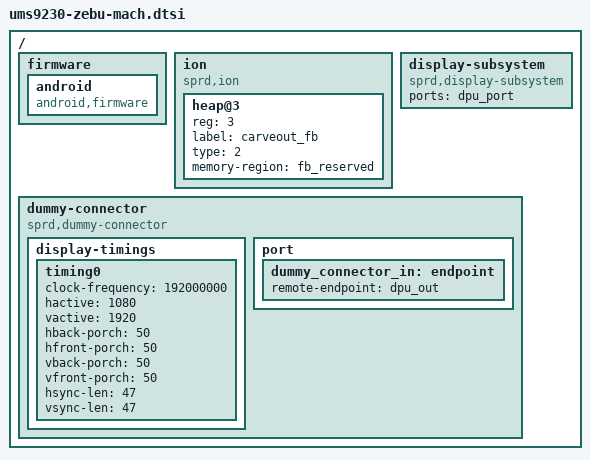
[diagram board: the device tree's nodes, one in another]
/*
 * Spreadtrum qogirl6 board common DTS file
 *
 * Copyright (C) 2018, Spreadtrum Communications Inc.
 *
 * This file is licensed under a dual GPLv2 or X11 license.
 */

#include "lcd/lcd_dummy_mipi.dtsi"

/ {
	firmware {
		android {
			compatible = "android,firmware";
		};
	};

	ion {
		compatible = "sprd,ion";
		#address-cells = <1>;
		#size-cells = <0>;

		heap@3 {
			reg = <3>;
			label = "carveout_fb";
			type = <2>;
			memory-region = <&fb_reserved>;
		};
	};

	display-subsystem {
		compatible = "sprd,display-subsystem";
		ports = <&dpu_port>;
		/*gsp = <&gsp>;*/
	};

	dummy-connector {
		compatible = "sprd,dummy-connector";

		display-timings {
			timing0 {
				clock-frequency = <192000000>;
				hactive = <1080>;
				vactive = <1920>;
				hback-porch = <50>;
				hfront-porch = <50>;
				vback-porch = <50>;
				vfront-porch = <50>;
				hsync-len = <47>;
				vsync-len = <47>;
			};
		};

		port {
			dummy_connector_in: endpoint {
				remote-endpoint = <&dpu_out>;
			};
		};
	};
};
